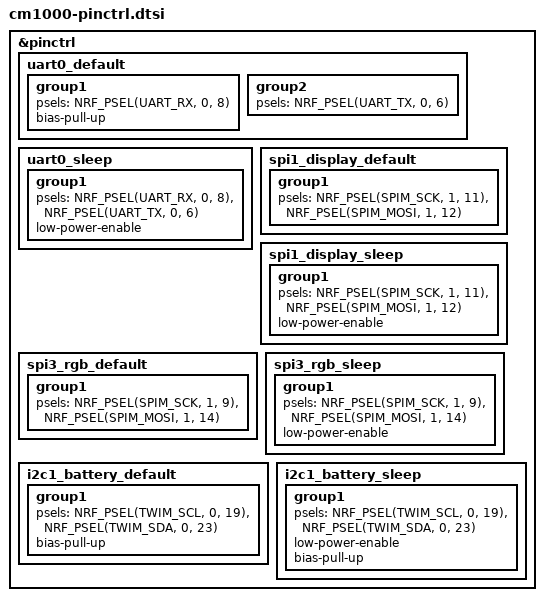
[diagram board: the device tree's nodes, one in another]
#include <dt-bindings/pinctrl/nrf-pinctrl.h>

&pinctrl {
    uart0_default: uart0_default {
        group1 {
            psels = <NRF_PSEL(UART_RX, 0, 8)>;
            bias-pull-up;
        };
        group2 {
            psels = <NRF_PSEL(UART_TX, 0, 6)>;
        };
    };

    uart0_sleep: uart0_sleep {
        group1 {
            psels = <NRF_PSEL(UART_RX, 0, 8)>,
                    <NRF_PSEL(UART_TX, 0, 6)>;
            low-power-enable;
        };
    };

    spi1_display_default: spi1_display_default {
        group1 {
            psels = <NRF_PSEL(SPIM_SCK, 1, 11)>,
                    <NRF_PSEL(SPIM_MOSI, 1, 12)>;
        };
    };

    spi1_display_sleep: spi1_display_sleep {
        group1 {
            psels = <NRF_PSEL(SPIM_SCK, 1, 11)>,
                    <NRF_PSEL(SPIM_MOSI, 1, 12)>;
            low-power-enable;
        };
    };

    spi3_rgb_default: spi3_rgb_default {
        group1 {
            psels = <NRF_PSEL(SPIM_SCK, 1, 9)>,
                    <NRF_PSEL(SPIM_MOSI, 1, 14)>;
        };
    };

    spi3_rgb_sleep: spi3_rgb_sleep {
        group1 {
            psels = <NRF_PSEL(SPIM_SCK, 1, 9)>,
                    <NRF_PSEL(SPIM_MOSI, 1, 14)>;
            low-power-enable;
        };
    };

    i2c1_battery_default: i2c1_battery_default {
        group1 {
            psels = <NRF_PSEL(TWIM_SCL, 0, 19)>,
                    <NRF_PSEL(TWIM_SDA, 0, 23)>;
            bias-pull-up;
        };
    };

    i2c1_battery_sleep: i2c1_battery_sleep {
        group1 {
            psels = <NRF_PSEL(TWIM_SCL, 0, 19)>,
                    <NRF_PSEL(TWIM_SDA, 0, 23)>;
            low-power-enable;
            bias-pull-up;
        };
    };
};
